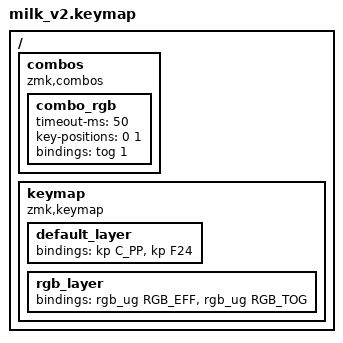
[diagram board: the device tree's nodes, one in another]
#include <behaviors.dtsi>
#include <dt-bindings/zmk/keys.h>
#include <dt-bindings/zmk/rgb.h>

/ {
    combos {
      compatible = "zmk,combos";
      combo_rgb {
        timeout-ms = <50>;
        key-positions = <0 1>;
        bindings = <&tog 1>;
        };
      };
    keymap {
        compatible = "zmk,keymap";

        default_layer {
        // -----------
        // |   F24   |
        // |   Play/Pause  |
            bindings = <
              &kp C_PP
              &kp F24
            >;
        };
        rgb_layer {
          bindings = <
            &rgb_ug RGB_EFF
            &rgb_ug RGB_TOG
            >;
        };
    };
};
